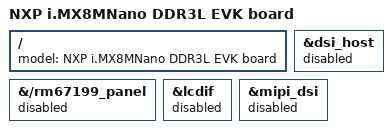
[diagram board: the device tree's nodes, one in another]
// SPDX-License-Identifier: GPL-2.0+
 /*
  * Copyright 2020 NXP
  */

#include "imx8mn-evk.dts"

/ {
	model = "NXP i.MX8MNano DDR3L EVK board";
};

&dsi_host {
	status = "disabled";
};

&{/rm67199_panel} {
	status = "disabled";
};

&lcdif {
	status = "disabled";
};

&mipi_dsi {
	status = "disabled";
};
